# ATSAMD21E17D register map
Vendor: Microchip Technology; Series: SAMD21; File version: 0
CPU: CM0+ r0p0, little endian, no MPU, no FPU, VTOR, 2 interrupt priority bits, 30 interrupts
Registers are 32-bit, read-write, reset 0x0 unless marked. A register's access mark holds for its fields unless they carry their own. Offsets are from the block's base; [hi:lo] are bit positions; {n}, {i} and the like mark numbered series; 'fields as' and 'values as' point back to an identical list.

## SYSCTRL — System Control
Base 0x40000800
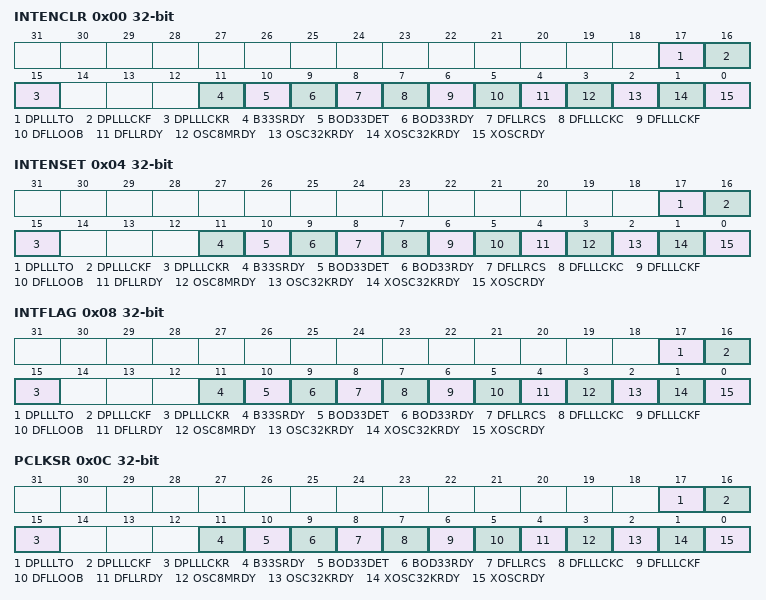
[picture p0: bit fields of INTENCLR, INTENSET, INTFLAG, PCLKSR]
0x00 INTENCLR write-1-clears — Interrupt Enable Clear
  [17] DPLLLTO — DPLL Lock Timeout Interrupt Enable
  [16] DPLLLCKF — DPLL Lock Fall Interrupt Enable
  [15] DPLLLCKR — DPLL Lock Rise Interrupt Enable
  [11] B33SRDY — BOD33 Synchronization Ready Interrupt Enable
  [10] BOD33DET — BOD33 Detection Interrupt Enable
  [9] BOD33RDY — BOD33 Ready Interrupt Enable
  [8] DFLLRCS — DFLL Reference Clock Stopped Interrupt Enable
  [7] DFLLLCKC — DFLL Lock Coarse Interrupt Enable
  [6] DFLLLCKF — DFLL Lock Fine Interrupt Enable
  [5] DFLLOOB — DFLL Out Of Bounds Interrupt Enable
  [4] DFLLRDY — DFLL Ready Interrupt Enable
  [3] OSC8MRDY — OSC8M Ready Interrupt Enable
  [2] OSC32KRDY — OSC32K Ready Interrupt Enable
  [1] XOSC32KRDY — XOSC32K Ready Interrupt Enable
  [0] XOSCRDY — XOSC Ready Interrupt Enable
0x04 INTENSET write-1-sets — Interrupt Enable Set
  fields as INTENCLR
0x08 INTFLAG write-1-clears — Interrupt Flag Status and Clear
  [17] DPLLLTO — DPLL Lock Timeout
  [16] DPLLLCKF — DPLL Lock Fall
  [15] DPLLLCKR — DPLL Lock Rise
  [11] B33SRDY — BOD33 Synchronization Ready
  [10] BOD33DET — BOD33 Detection
  [9] BOD33RDY — BOD33 Ready
  [8] DFLLRCS — DFLL Reference Clock Stopped
  [7] DFLLLCKC — DFLL Lock Coarse
  [6] DFLLLCKF — DFLL Lock Fine
  [5] DFLLOOB — DFLL Out Of Bounds
  [4] DFLLRDY — DFLL Ready
  [3] OSC8MRDY — OSC8M Ready
  [2] OSC32KRDY — OSC32K Ready
  [1] XOSC32KRDY — XOSC32K Ready
  [0] XOSCRDY — XOSC Ready
0x0C PCLKSR ro — Power and Clocks Status
  fields as INTFLAG
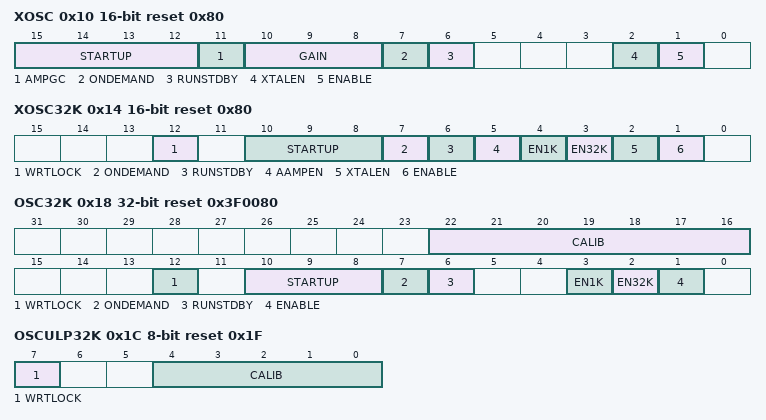
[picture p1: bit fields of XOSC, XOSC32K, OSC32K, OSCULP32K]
0x10 XOSC 16-bit reset 0x80 — External Multipurpose Crystal Oscillator (XOSC) Control
  [15:12] STARTUP — Start-Up Time
    0=CYCLE1 (31 us); 1=CYCLE2 (61 us); 2=CYCLE4 (122 us); 3=CYCLE8 (244 us); 4=CYCLE16 (488 us); 5=CYCLE32 (977 us); 6=CYCLE64 (1953 us); 7=CYCLE128 (3906 us); 8=CYCLE256 (7813 us); 9=CYCLE512 (15625 us); 10=CYCLE1024 (31250 us); 11=CYCLE2048 (62500 us); 12=CYCLE4096 (125000 us); 13=CYCLE8192 (250000 us); 14=CYCLE16384 (500000 us); 15=CYCLE32768 (1000000 us)
  [11] AMPGC — Automatic Amplitude Gain Control
  [10:8] GAIN — Oscillator Gain
    0=2MHz; 1=4MHz; 2=8MHz; 3=16MHz; 4=30MHz
  [7] ONDEMAND — On Demand Control
  [6] RUNSTDBY — Run in Standby
  [2] XTALEN — Crystal Oscillator Enable
  [1] ENABLE — Oscillator Enable
0x14 XOSC32K 16-bit reset 0x80 — 32kHz External Crystal Oscillator (XOSC32K) Control
  [12] WRTLOCK — Write Lock
  [10:8] STARTUP — Oscillator Start-Up Time
    0=CYCLE1 (0.122 ms); 1=CYCLE32 (1.068 ms); 2=CYCLE2048 (62.592 ms); 3=CYCLE4096 (125.092 ms); 4=CYCLE16384 (500.092 ms); 5=CYCLE32768 (1000.092 ms); 6=CYCLE65536 (2000.092 ms); 7=CYCLE131072 (4000.092 ms)
  [7] ONDEMAND — On Demand Control
  [6] RUNSTDBY — Run in Standby
  [5] AAMPEN — Automatic Amplitude Control Enable
  [4] EN1K — 1kHz Output Enable
  [3] EN32K — 32kHz Output Enable
  [2] XTALEN — Crystal Oscillator Enable
  [1] ENABLE — Oscillator Enable
0x18 OSC32K reset 0x3F0080 — 32kHz Internal Oscillator (OSC32K) Control
  [22:16] CALIB — Oscillator Calibration
  [12] WRTLOCK — Write Lock
  [10:8] STARTUP — Oscillator Start-Up Time
    0=CYCLE3 (0.092 ms); 1=CYCLE4 (0.122 ms); 2=CYCLE6 (0.183 ms); 3=CYCLE10 (0.305 ms); 4=CYCLE18 (0.549 ms); 5=CYCLE34 (1.038 ms); 6=CYCLE66 (2.014 ms); 7=CYCLE130 (3.967 ms)
  [7] ONDEMAND — On Demand Control
  [6] RUNSTDBY — Run in Standby
  [3] EN1K — 1kHz Output Enable
  [2] EN32K — 32kHz Output Enable
  [1] ENABLE — Oscillator Enable
0x1C OSCULP32K 8-bit reset 0x1F — 32kHz Ultra Low Power Internal Oscillator (OSCULP32K) Control
  [7] WRTLOCK — Write Lock
  [4:0] CALIB — Oscillator Calibration
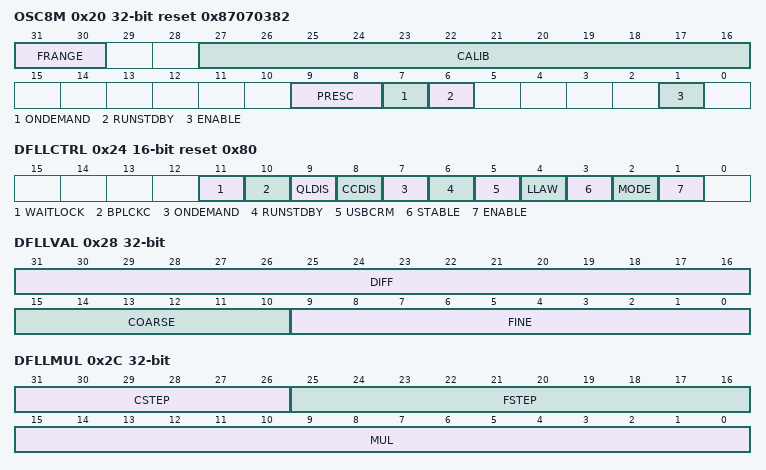
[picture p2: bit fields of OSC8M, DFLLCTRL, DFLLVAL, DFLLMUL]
0x20 OSC8M reset 0x87070382 — 8MHz Internal Oscillator (OSC8M) Control
  [31:30] FRANGE — Oscillator Frequency Range
    0=4 to 6MHz; 1=6 to 8MHz; 2=8 to 11MHz; 3=11 to 15MHz
  [27:16] CALIB — Oscillator Calibration
  [9:8] PRESC — Oscillator Prescaler
  [7] ONDEMAND — On Demand Control
  [6] RUNSTDBY — Run in Standby
  [1] ENABLE — Oscillator Enable
0x24 DFLLCTRL 16-bit reset 0x80 — DFLL48M Control
  [11] WAITLOCK
  [10] BPLCKC — Bypass Coarse Lock
  [9] QLDIS — Quick Lock Disable
  [8] CCDIS — Chill Cycle Disable
  [7] ONDEMAND — On Demand Control
  [6] RUNSTDBY — Run in Standby
  [5] USBCRM — USB Clock Recovery Mode
  [4] LLAW — Lose Lock After Wake
  [3] STABLE — Stable DFLL Frequency
  [2] MODE — Operating Mode Selection
  [1] ENABLE — DFLL Enable
0x28 DFLLVAL — DFLL48M Value
  [31:16] DIFF — Multiplication Ratio Difference
  [15:10] COARSE — Coarse Value
  [9:0] FINE — Fine Value
0x2C DFLLMUL — DFLL48M Multiplier
  [31:26] CSTEP — Coarse Maximum Step
  [25:16] FSTEP — Fine Maximum Step
  [15:0] MUL — DFLL Multiply Factor
0x30 DFLLSYNC 8-bit — DFLL48M Synchronization
  [7] READREQ — Read Request
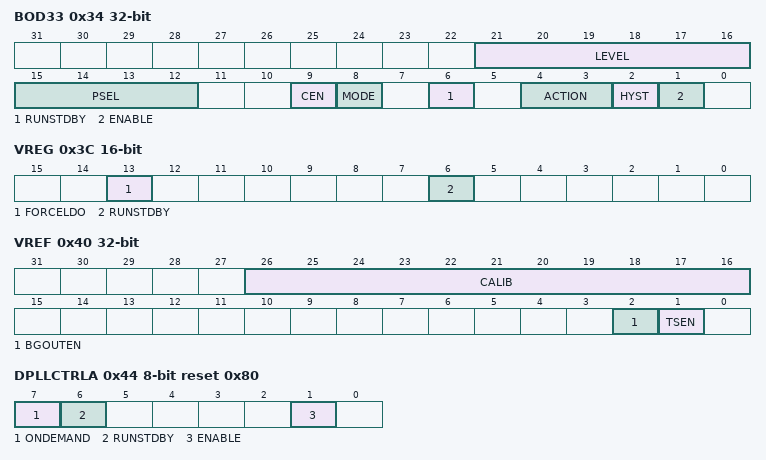
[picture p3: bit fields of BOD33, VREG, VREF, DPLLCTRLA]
0x34 BOD33 — 3.3V Brown-Out Detector (BOD33) Control
  [21:16] LEVEL — BOD33 Threshold Level
  [15:12] PSEL — Prescaler Select
    0=DIV2 (Divide clock by 2); 1=DIV4 (Divide clock by 4); 2=DIV8 (Divide clock by 8); 3=DIV16 (Divide clock by 16); 4=DIV32 (Divide clock by 32); 5=DIV64 (Divide clock by 64); 6=DIV128 (Divide clock by 128); 7=DIV256 (Divide clock by 256); 8=DIV512 (Divide clock by 512); 9=DIV1K (Divide clock by 1024); 10=DIV2K (Divide clock by 2048); 11=DIV4K (Divide clock by 4096); 12=DIV8K (Divide clock by 8192); 13=DIV16K (Divide clock by 16384); 14=DIV32K (Divide clock by 32768); 15=DIV64K (Divide clock by 65536)
  [9] CEN — Clock Enable
  [8] MODE — Operation Mode
  [6] RUNSTDBY — Run in Standby
  [4:3] ACTION — BOD33 Action
    0=NONE (No action); 1=RESET (The BOD33 generates a reset); 2=INTERRUPT (The BOD33 generates an interrupt)
  [2] HYST — Hysteresis
  [1] ENABLE
0x3C VREG 16-bit — Voltage Regulator System (VREG) Control
  [13] FORCELDO — Force LDO Voltage Regulator
  [6] RUNSTDBY — Run in Standby
0x40 VREF — Voltage References System (VREF) Control
  [26:16] CALIB — Bandgap Voltage Generator Calibration
  [2] BGOUTEN — Bandgap Output Enable
  [1] TSEN — Temperature Sensor Enable
0x44 DPLLCTRLA 8-bit reset 0x80 — DPLL Control A
  [7] ONDEMAND — On Demand Clock Activation
  [6] RUNSTDBY — Run in Standby
  [1] ENABLE — DPLL Enable
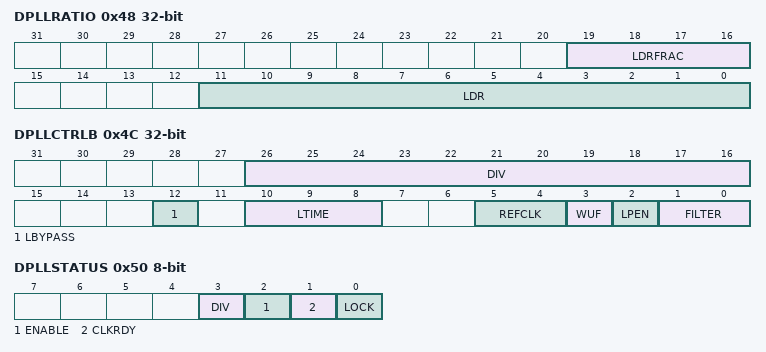
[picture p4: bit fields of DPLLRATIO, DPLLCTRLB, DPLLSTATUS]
0x48 DPLLRATIO — DPLL Ratio Control
  [19:16] LDRFRAC — Loop Divider Ratio Fractional Part
  [11:0] LDR — Loop Divider Ratio
0x4C DPLLCTRLB — DPLL Control B
  [26:16] DIV — Clock Divider
  [12] LBYPASS — Lock Bypass
  [10:8] LTIME — Lock Time
    0=DEFAULT (No time-out); {v}={v+4}MS (Time-out if no lock within {v+4} ms) (v=4..7)
  [5:4] REFCLK — Reference Clock Selection
    0=REF0 (CLK_DPLL_REF0 clock reference); 1=REF1 (CLK_DPLL_REF1 clock reference); 2=GCLK (GCLK_DPLL clock reference)
  [3] WUF — Wake Up Fast
  [2] LPEN — Low-Power Enable
  [1:0] FILTER — Proportional Integral Filter Selection
    0=DEFAULT (Default filter mode); 1=LBFILT (Low bandwidth filter); 2=HBFILT (High bandwidth filter); 3=HDFILT (High damping filter)
0x50 DPLLSTATUS 8-bit ro
  [3] DIV — Divider Enable
  [2] ENABLE — DPLL Enable
  [1] CLKRDY — Output Clock Ready
  [0] LOCK — DPLL Lock Status
